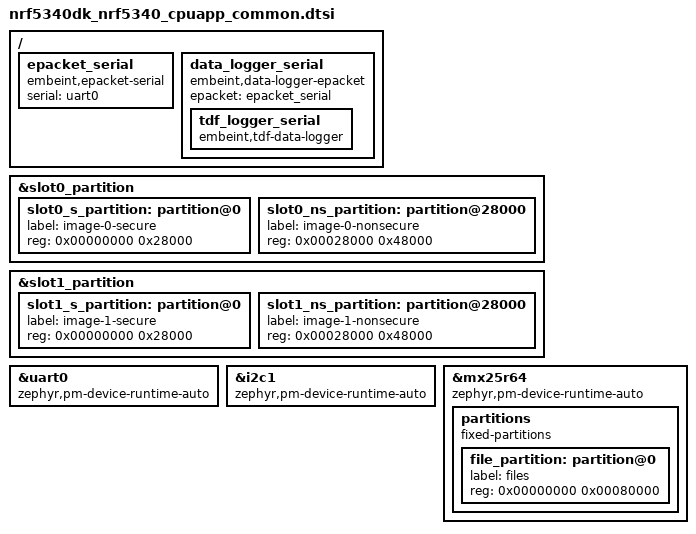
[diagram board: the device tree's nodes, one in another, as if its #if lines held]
#include <common/infuse_bluetooth.dtsi>

/ {
	epacket_serial: epacket_serial {
		compatible = "embeint,epacket-serial";
		serial = <&uart0>;
	};

	data_logger_serial: data_logger_serial {
		compatible = "embeint,data-logger-epacket", "embeint,data-logger";
		epacket = <&epacket_serial>;

		tdf_logger_serial: tdf_logger_serial {
			compatible = "embeint,tdf-data-logger";
		};
	};

	data_logger_flash: data_logger_flash {
		compatible = "embeint,data-logger-flash-map", "embeint,data-logger";
		partition = <&data_logger_partition>;

		tdf_logger_flash: tdf_logger_flash {
			compatible = "embeint,tdf-data-logger";
		};
	};
};

/* Allocate more ROM to non-secure application */
/delete-node/ &slot0_s_partition;
/delete-node/ &slot0_ns_partition;
/delete-node/ &slot1_s_partition;
/delete-node/ &slot1_ns_partition;

&slot0_partition {
	slot0_s_partition: partition@0 {
		label = "image-0-secure";
		reg = <0x00000000 0x28000>;
	};

	slot0_ns_partition: partition@28000 {
		label = "image-0-nonsecure";
		reg = <0x00028000 0x48000>;
	};
};

&slot1_partition {
	slot1_s_partition: partition@0 {
		label = "image-1-secure";
		reg = <0x00000000 0x28000>;
	};

	slot1_ns_partition: partition@28000 {
		label = "image-1-nonsecure";
		reg = <0x00028000 0x48000>;
	};
};

&uart0 {
	zephyr,pm-device-runtime-auto;
};
&i2c1 {
	zephyr,pm-device-runtime-auto;
};
&mx25r64 {
	zephyr,pm-device-runtime-auto;

	partitions {
		compatible = "fixed-partitions";
		#address-cells = <1>;
		#size-cells = <1>;

		file_partition: partition@0 {
			label = "files";
			reg = <0x00000000 0x00080000>;
		};
		data_logger_partition: partition@80000 {
			label = "data_logger";
			reg = <0x00080000 0x00780000>;
		};
	};
};

#ifdef INFUSE_IS_BOOTLOADER

/* Bootloader doesn't know about external flash */
/delete-node/ &data_logger_flash;
/delete-node/ &data_logger_partition;

#endif /* INFUSE_IS_BOOTLOADER */
